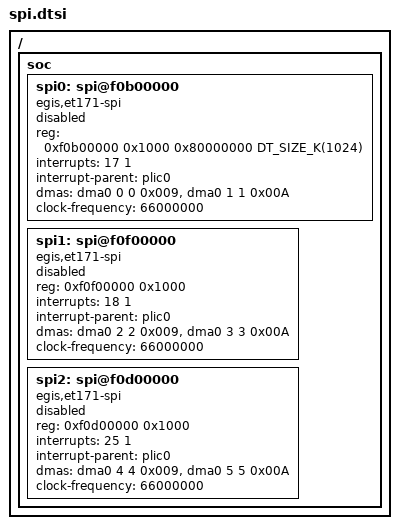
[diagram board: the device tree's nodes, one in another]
/ {
	soc {
		spi0: spi@f0b00000 {
			compatible = "egis,et171-spi";
			reg = <0xf0b00000 0x1000
			       0x80000000 DT_SIZE_K(1024)>;
			reg-names = "control", "mem";
			interrupts = <17 1>;
			interrupt-parent = <&plic0>;
			dmas = <&dma0 0 0 0x009>,
			       <&dma0 1 1 0x00A>;
			dma-names = "tx", "rx";
			#address-cells = <1>;
			#size-cells = <0>;
			clock-frequency = <66000000>;
			status = "disabled";
		};

		spi1: spi@f0f00000 {
			compatible = "egis,et171-spi";
			reg = <0xf0f00000 0x1000>;
			reg-names = "control";
			interrupts = <18 1>;
			interrupt-parent = <&plic0>;
			dmas = <&dma0 2 2 0x009>,
			       <&dma0 3 3 0x00A>;
			dma-names = "tx", "rx";
			#address-cells = <1>;
			#size-cells = <0>;
			clock-frequency = <66000000>;
			status = "disabled";
		};

		spi2: spi@f0d00000 {
			compatible = "egis,et171-spi";
			reg = <0xf0d00000 0x1000>;
			reg-names = "control";
			interrupts = <25 1>;
			interrupt-parent = <&plic0>;
			dmas = <&dma0 4 4 0x009>,
			       <&dma0 5 5 0x00A>;
			dma-names = "tx", "rx";
			#address-cells = <1>;
			#size-cells = <0>;
			clock-frequency = <66000000>;
			status = "disabled";
		};
	};
};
